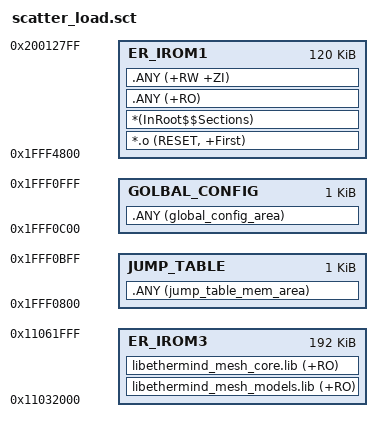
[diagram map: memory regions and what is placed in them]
; *************************************************************
; *** Scatter-Loading Description File generated by uVision ***
; *************************************************************

LR_IROM1 0x1fff4800 0x0001e000{;0x0001e800 {  ; load region size_region
  ER_IROM1 0x1fff4800 0x0001e000  {  ; load address = execution address
   *.o (RESET, +First)
   *(InRoot$$Sections)
   .ANY (+RO)  
   .ANY (+RW +ZI)
  }
 }
  
 
LR_IROM2  0x1fff0800 0x00800 {
  JUMP_TABLE 0x1fff0800 0x00400  {
   .ANY (jump_table_mem_area) 
	
  }
  GOLBAL_CONFIG 0x1fff0c00 0x00400  {
   .ANY (global_config_area) 
	
  }  
 } 

LR_IROM3  0x11032000 0x030000 {
  ER_IROM3 0x11032000 0x030000  {  ; load address = execution address
   libethermind_mesh_models.lib (+RO) 
   ;libethermind_utils.lib (+RO) 
   libethermind_mesh_core.lib (+RO) 
   ;devinfoservice.o(+RO)
   ;gatt*.o(+RO)
   ;gatt_client.o(+RO)
   ;cli_*.o (+RO)
   ;sm*.o (+RO)
   ;appl_*.o (+RO)
  }
 }  


